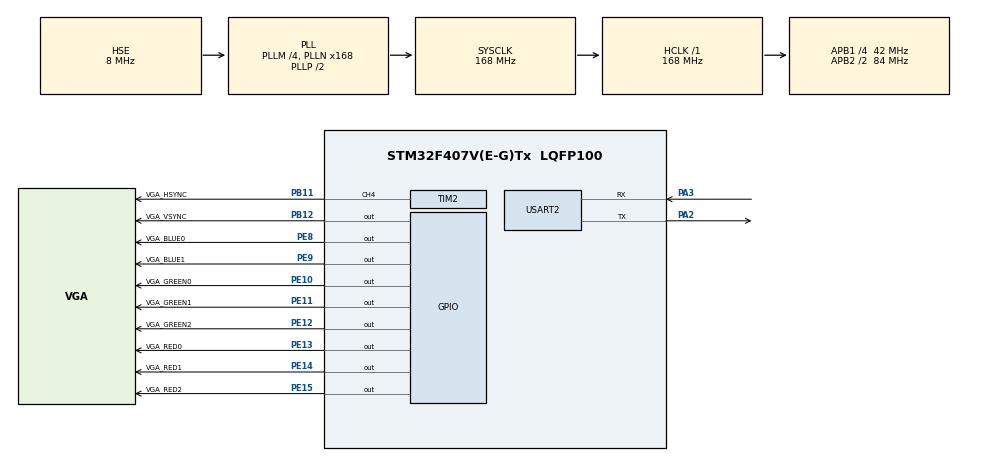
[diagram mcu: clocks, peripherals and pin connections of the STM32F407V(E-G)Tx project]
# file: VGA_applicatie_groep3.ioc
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Dma.Request0=TIM1_UP
Dma.TIM1_UP.0.Direction=DMA_MEMORY_TO_PERIPH
Dma.TIM1_UP.0.FIFOMode=DMA_FIFOMODE_DISABLE
Dma.TIM1_UP.0.Instance=DMA2_Stream5
Dma.TIM1_UP.0.MemDataAlignment=DMA_MDATAALIGN_BYTE
Dma.TIM1_UP.0.MemInc=DMA_MINC_ENABLE
Dma.TIM1_UP.0.Mode=DMA_NORMAL
Dma.TIM1_UP.0.PeriphDataAlignment=DMA_PDATAALIGN_BYTE
Dma.TIM1_UP.0.PeriphInc=DMA_PINC_DISABLE
Dma.TIM1_UP.0.Priority=DMA_PRIORITY_VERY_HIGH
Mcu.Family=STM32F4
Mcu.Name=STM32F407V(E-G)Tx
Mcu.Package=LQFP100
NVIC.DMA2_Stream5_IRQn=true\:0\:0\:false\:false\:true\:false\:true\:true
NVIC.PriorityGroup=NVIC_PRIORITYGROUP_4
NVIC.TIM2_IRQn=true\:0\:0\:true\:false\:true\:true\:true\:true
NVIC.USART2_IRQn=true\:0\:0\:false\:false\:true\:true\:true\:true
PA13.Mode=Serial_Wire
PA13.Signal=SYS_JTMS-SWDIO
PA14.Mode=Serial_Wire
PA14.Signal=SYS_JTCK-SWCLK
PA2.Mode=Asynchronous
PA2.Signal=USART2_TX
PA3.Mode=Asynchronous
PA3.Signal=USART2_RX
PB11.GPIO_Label=VGA_HSYNC
PB11.GPIO_Speed=GPIO_SPEED_FREQ_VERY_HIGH
PB11.Signal=S_TIM2_CH4
PB12.GPIO_Label=VGA_VSYNC
PB12.GPIO_PuPd=GPIO_NOPULL
PB12.GPIO_Speed=GPIO_SPEED_FREQ_VERY_HIGH
PB12.Signal=GPIO_Output
PE10.GPIO_Label=VGA_GREEN0
PE10.GPIO_PuPd=GPIO_NOPULL
PE10.GPIO_Speed=GPIO_SPEED_FREQ_VERY_HIGH
PE10.Signal=GPIO_Output
PE11.GPIO_Label=VGA_GREEN1
PE11.GPIO_PuPd=GPIO_NOPULL
PE11.GPIO_Speed=GPIO_SPEED_FREQ_VERY_HIGH
PE11.Signal=GPIO_Output
PE12.GPIO_Label=VGA_GREEN2
PE12.GPIO_PuPd=GPIO_NOPULL
PE12.GPIO_Speed=GPIO_SPEED_FREQ_VERY_HIGH
PE12.Signal=GPIO_Output
PE13.GPIO_Label=VGA_RED0
PE13.GPIO_PuPd=GPIO_NOPULL
PE13.GPIO_Speed=GPIO_SPEED_FREQ_VERY_HIGH
PE13.Signal=GPIO_Output
PE14.GPIO_Label=VGA_RED1
PE14.GPIO_PuPd=GPIO_NOPULL
PE14.GPIO_Speed=GPIO_SPEED_FREQ_VERY_HIGH
PE14.Signal=GPIO_Output
PE15.GPIO_Label=VGA_RED2
PE15.GPIO_PuPd=GPIO_NOPULL
PE15.GPIO_Speed=GPIO_SPEED_FREQ_VERY_HIGH
PE15.Signal=GPIO_Output
PE8.GPIO_Label=VGA_BLUE0
PE8.GPIO_PuPd=GPIO_NOPULL
PE8.GPIO_Speed=GPIO_SPEED_FREQ_VERY_HIGH
PE8.Signal=GPIO_Output
PE9.GPIO_Label=VGA_BLUE1
PE9.GPIO_PuPd=GPIO_NOPULL
PE9.GPIO_Speed=GPIO_SPEED_FREQ_VERY_HIGH
PE9.Signal=GPIO_Output
PH0-OSC_IN.Mode=HSE-External-Oscillator
PH0-OSC_IN.Signal=RCC_OSC_IN
PH1-OSC_OUT.Mode=HSE-External-Oscillator
PH1-OSC_OUT.Signal=RCC_OSC_OUT
ProjectManager.HeapSize=0x200
ProjectManager.StackSize=0x400
ProjectManager.TargetToolchain=STM32CubeIDE
RCC.48MHZClocksFreq_Value=84000000
RCC.AHBFreq_Value=168000000
RCC.APB1CLKDivider=RCC_HCLK_DIV4
RCC.APB1Freq_Value=42000000
RCC.APB1TimFreq_Value=84000000
RCC.APB2CLKDivider=RCC_HCLK_DIV2
RCC.APB2Freq_Value=84000000
RCC.APB2TimFreq_Value=168000000
RCC.CortexFreq_Value=168000000
RCC.HCLKFreq_Value=168000000
RCC.HSE_VALUE=8000000
RCC.HSI_VALUE=16000000
RCC.LSE_VALUE=32768
RCC.PLLM=4
RCC.PLLN=168
RCC.PLLSourceVirtual=RCC_PLLSOURCE_HSE
RCC.SYSCLKFreq_VALUE=168000000
RCC.SYSCLKSource=RCC_SYSCLKSOURCE_PLLCLK
RCC.VCOOutputFreq_Value=336000000
SH.S_TIM2_CH4.0=TIM2_CH4,PWM Generation4 CH4
TIM1.Period=VGA_TIM1_PERIODE
TIM1.Prescaler=VGA_TIM1_PRESCALE
TIM2.AutoReloadPreload=TIM_AUTORELOAD_PRELOAD_DISABLE
TIM2.Channel-PWM\ Generation3\ No\ Output=TIM_CHANNEL_3
TIM2.Channel-PWM\ Generation4\ CH4=TIM_CHANNEL_4
TIM2.OCPolarity_3=TIM_OCPOLARITY_LOW
TIM2.OCPolarity_4=TIM_OCPOLARITY_LOW
TIM2.Period=VGA_TIM2_HSYNC_PERIODE
TIM2.Prescaler=VGA_TIM2_HSYNC_PRESCALE
TIM2.Pulse-PWM\ Generation3\ No\ Output=VGA_TIM2_HTRIGGER_START - VGA_TIM2_DMA_DELAY
TIM2.Pulse-PWM\ Generation4\ CH4=VGA_TIM2_HSYNC_IMP
USART2.VirtualMode=VM_ASYNC
VP_TIM1_VS_ClockSourceINT.Mode=Internal
VP_TIM2_VS_no_output3.Mode=PWM Generation3 No Output
board=custom

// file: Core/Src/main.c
/* USER CODE BEGIN Header */
/**
  ******************************************************************************
  * @file           : main.c
  * @brief          : Main program body
  ******************************************************************************
  * @attention
  *
  * <h2><center>&copy; Copyright (c) 2020 STMicroelectronics.
  * All rights reserved.</center></h2>
  *
  * ThisIO_func software component is licensed by ST under BSD 3-Clause license,
  * the "License"; You may not use this file except in compliance with the
  * License. You may obtain a copy of the License at:
  *                        opensource.org/licenses/BSD-3-Clause
  *
  ******************************************************************************
  */
/* USER CODE END Header */
#include "main.h"

/* USER CODE BEGIN PV */
input_vars input;
/* USER CODE END PV */

void SystemClock_Config(void);

int main(void)
{

  /* MCU Configuration--------------------------------------------------------*/

  /* Reset of all peripherals, Initializes the Flash interface and the Systick. */
  HAL_Init();

  /* Configure the system clock */
  SystemClock_Config();

  /* Initialize all configured peripherals */
  MX_GPIO_Init();
  MX_DMA_Init();
  MX_TIM1_Init();
  MX_TIM2_Init();
  MX_USART2_UART_Init();
  /* USER CODE BEGIN 2 */

  UB_VGA_Screen_Init(); // Init VGA-Screen

  memset(&input,0,sizeof(input));
  // HAl wants a memory location to store the charachter it receives from the UART
  // We will pass it an array, but we will not use it. We declare our own variable in the interupt handler
  // See stm32f4xx_it.c
  HAL_UART_Receive_IT(&huart2, input.byte_buffer_rx, BYTE_BUFLEN);

  example();
  /* USER CODE END 2 */

  /* Infinite loop */
  while (1)
  {

  }
}

void SystemClock_Config(void)
{
  RCC_OscInitTypeDef RCC_OscInitStruct = {0};
  RCC_ClkInitTypeDef RCC_ClkInitStruct = {0};

  /** Configure the main internal regulator output voltage
  */
  __HAL_RCC_PWR_CLK_ENABLE();
  __HAL_PWR_VOLTAGESCALING_CONFIG(PWR_REGULATOR_VOLTAGE_SCALE1);
  /** Initializes the RCC Oscillators according to the specified parameters
  * in the RCC_OscInitTypeDef structure.
  */
  RCC_OscInitStruct.OscillatorType = RCC_OSCILLATORTYPE_HSE;
  RCC_OscInitStruct.HSEState = RCC_HSE_ON;
  RCC_OscInitStruct.PLL.PLLState = RCC_PLL_ON;
  RCC_OscInitStruct.PLL.PLLSource = RCC_PLLSOURCE_HSE;
  RCC_OscInitStruct.PLL.PLLM = 4;
  RCC_OscInitStruct.PLL.PLLN = 168;
  RCC_OscInitStruct.PLL.PLLP = RCC_PLLP_DIV2;
  RCC_OscInitStruct.PLL.PLLQ = 4;
  if (HAL_RCC_OscConfig(&RCC_OscInitStruct) != HAL_OK)
  {
    Error_Handler();
  }
  /** Initializes the CPU, AHB and APB buses clocks
  */
  RCC_ClkInitStruct.ClockType = RCC_CLOCKTYPE_HCLK|RCC_CLOCKTYPE_SYSCLK
                              |RCC_CLOCKTYPE_PCLK1|RCC_CLOCKTYPE_PCLK2;
  RCC_ClkInitStruct.SYSCLKSource = RCC_SYSCLKSOURCE_PLLCLK;
  RCC_ClkInitStruct.AHBCLKDivider = RCC_SYSCLK_DIV1;
  RCC_ClkInitStruct.APB1CLKDivider = RCC_HCLK_DIV4;
  RCC_ClkInitStruct.APB2CLKDivider = RCC_HCLK_DIV2;

  if (HAL_RCC_ClockConfig(&RCC_ClkInitStruct, FLASH_LATENCY_5) != HAL_OK)
  {
    Error_Handler();
  }
}

/* USER CODE BEGIN 4 */

#ifdef __GNUC__
	#define USART_PRINTF int __io_putchar(int ch)		//With GCC/RAISONANCE printf calls __io_putchar()
#else
	#define USART_PRINTF int fputc(int ch, FILE *f)		//With other compiler printf calls fputc()
#endif /* __GNUC__ */

//Retargets the C library printf function to the USART
USART_PRINTF
{
	HAL_UART_Transmit(&huart2, (uint8_t *)&ch, 1, 0xFFFF);	//Write character to UART2
	return ch;												//Return the character
}

/* USER CODE END 4 */

void Error_Handler(void)
{
}

/************************ (C) COPYRIGHT STMicroelectronics *****END OF FILE****/
